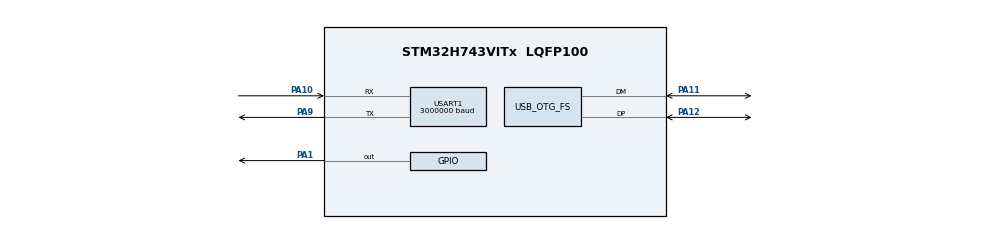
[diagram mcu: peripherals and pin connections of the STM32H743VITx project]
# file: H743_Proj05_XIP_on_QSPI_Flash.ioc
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Mcu.Family=STM32H7
Mcu.Name=STM32H743VITx
Mcu.Package=LQFP100
NVIC.OTG_FS_IRQn=true\:0\:0\:false\:false\:true\:false\:true
NVIC.PriorityGroup=NVIC_PRIORITYGROUP_4
NVIC.TIM8_UP_TIM13_IRQn=true\:0\:0\:false\:false\:true\:false\:true
NVIC.TimeBase=TIM8_UP_TIM13_IRQn
NVIC.TimeBaseIP=TIM13
PA1.GPIO_PuPd=GPIO_PULLUP
PA1.PinState=GPIO_PIN_SET
PA1.Signal=GPIO_Output
PA10.GPIO_Speed=GPIO_SPEED_FREQ_MEDIUM
PA10.Mode=Asynchronous
PA10.Signal=USART1_RX
PA11.GPIO_Speed=GPIO_SPEED_FREQ_MEDIUM
PA11.Mode=Device_Only
PA11.Signal=USB_OTG_FS_DM
PA12.GPIO_PuPd=GPIO_NOPULL
PA12.GPIO_Speed=GPIO_SPEED_FREQ_MEDIUM
PA12.Mode=Device_Only
PA12.Signal=USB_OTG_FS_DP
PA13\ (JTMS/SWDIO).Mode=Serial_Wire
PA13\ (JTMS/SWDIO).Signal=DEBUG_JTMS-SWDIO
PA14\ (JTCK/SWCLK).Mode=Serial_Wire
PA14\ (JTCK/SWCLK).Signal=DEBUG_JTCK-SWCLK
PA9.GPIO_Speed=GPIO_SPEED_FREQ_MEDIUM
PA9.Mode=Asynchronous
PA9.Signal=USART1_TX
PB6.GPIO_PuPd=GPIO_PULLUP
PB6.GPIO_Speed=GPIO_SPEED_FREQ_HIGH
PB6.Signal=QUADSPI_BK1_NCS
PC14-OSC32_IN\ (OSC32_IN).Mode=LSE-External-Oscillator
PC14-OSC32_IN\ (OSC32_IN).Signal=RCC_OSC32_IN
PC15-OSC32_OUT\ (OSC32_OUT).Mode=LSE-External-Oscillator
PC15-OSC32_OUT\ (OSC32_OUT).Signal=RCC_OSC32_OUT
PH0-OSC_IN\ (PH0).Mode=HSE-External-Oscillator
PH0-OSC_IN\ (PH0).Signal=RCC_OSC_IN
PH1-OSC_OUT\ (PH1).Mode=HSE-External-Oscillator
PH1-OSC_OUT\ (PH1).Signal=RCC_OSC_OUT
ProjectManager.HeapSize=0x200
ProjectManager.StackSize=0x400
ProjectManager.TargetToolchain=STM32CubeIDE
RCC.ADCFreq_Value=50390625
RCC.APB1Freq_Value=120000000
RCC.APB2Freq_Value=120000000
RCC.APB3Freq_Value=120000000
RCC.APB4Freq_Value=120000000
RCC.CortexFreq_Value=480000000
RCC.D1PPRE=RCC_APB3_DIV2
RCC.D2PPRE1=RCC_APB1_DIV2
RCC.D2PPRE2=RCC_APB2_DIV2
RCC.D3PPRE=RCC_APB4_DIV2
RCC.DIVM1=5
RCC.DIVM3=5
RCC.DIVN1=192
RCC.DIVN3=192
RCC.DIVQ3=20
RCC.HCLKFreq_Value=240000000
RCC.HPRE=RCC_HCLK_DIV2
RCC.RTCClockSelection=RCC_RTCCLKSOURCE_LSE
RCC.SYSCLKFreq_VALUE=480000000
RCC.SYSCLKSource=RCC_SYSCLKSOURCE_PLLCLK
RCC.USBCLockSelection=RCC_USBCLKSOURCE_PLL3
RCC.USBFreq_Value=48000000
USART1.BaudRate=3000000
USART1.VirtualMode-Asynchronous=VM_ASYNC
USB_DEVICE.CLASS_NAME_FS=CDC
USB_DEVICE.VirtualMode-CDC_FS=Cdc
USB_DEVICE.VirtualModeFS=Cdc_FS
USB_OTG_FS.VirtualMode=Device_Only
VP_RTC_VS_RTC_Activate.Mode=RTC_Enabled
VP_SYS_VS_tim13.Mode=TIM13
VP_USB_DEVICE_VS_USB_DEVICE_CDC_FS.Mode=CDC_FS
board=custom

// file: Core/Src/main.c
/* USER CODE BEGIN Header */
/**
  ******************************************************************************
  * @file           : main.c
  * @brief          : Main program body
  ******************************************************************************
  * @attention
  *
  * <h2><center>&copy; Copyright (c) 2020 STMicroelectronics.
  * All rights reserved.</center></h2>
  *
  * This software component is licensed by ST under BSD 3-Clause license,
  * the "License"; You may not use this file except in compliance with the
  * License. You may obtain a copy of the License at:
  *                        opensource.org/licenses/BSD-3-Clause
  *
  ******************************************************************************
  */
/* USER CODE END Header */

#include "main.h"
#include "usb_device.h"

/* USER CODE BEGIN Includes */
#include "usbd_cdc_if.h"
/* USER CODE END Includes */

RTC_HandleTypeDef hrtc;

UART_HandleTypeDef huart1;

/* USER CODE BEGIN PV */
char sOutput[160];
/* USER CODE END PV */

void SystemClock_Config(void);
static void MX_GPIO_Init(void);
static void MX_RTC_Init(void);
static void MX_USART1_UART_Init(void);

int main(void)
{
  /* USER CODE BEGIN 1 */

	/* Enable I-Cache */
	//SCB_EnableICache();

	/* Enable D-Cache */
	//SCB_EnableDCache();

  /* USER CODE END 1 */

  /* MCU Configuration--------------------------------------------------------*/

  /* Reset of all peripherals, Initializes the Flash interface and the Systick. */
  HAL_Init();

  /* Configure the system clock */
  SystemClock_Config();

  /* Initialize all configured peripherals */
  MX_GPIO_Init();
  MX_RTC_Init();
  MX_USART1_UART_Init();
  MX_USB_DEVICE_Init();

  /* Infinite loop */
  /* USER CODE BEGIN WHILE */
  uint16_t i=0;
  while (1)
  {
		snprintf(sOutput,159,"[H743_Proj05_XIP_on_QSPI_flash]: In while cycle %04X.\r\n",i++);
		HAL_UART_Transmit(&huart1, (uint8_t*)sOutput,strlen(sOutput), 0xFFFF);
		CDC_Transmit_FS((uint8_t*)sOutput,strlen(sOutput));
		HAL_GPIO_TogglePin(GPIOA, GPIO_PIN_1);
		HAL_Delay(2);
    /* USER CODE END WHILE */

  }
}

void SystemClock_Config(void)
{
  RCC_OscInitTypeDef RCC_OscInitStruct = {0};
  RCC_ClkInitTypeDef RCC_ClkInitStruct = {0};
  RCC_PeriphCLKInitTypeDef PeriphClkInitStruct = {0};

  /** Supply configuration update enable
  */
  HAL_PWREx_ConfigSupply(PWR_LDO_SUPPLY);
  /** Configure the main internal regulator output voltage
  */
  __HAL_PWR_VOLTAGESCALING_CONFIG(PWR_REGULATOR_VOLTAGE_SCALE0);

  while(!__HAL_PWR_GET_FLAG(PWR_FLAG_VOSRDY)) {}
  /** Configure LSE Drive Capability
  */
  HAL_PWR_EnableBkUpAccess();
  __HAL_RCC_LSEDRIVE_CONFIG(RCC_LSEDRIVE_LOW);
  /** Macro to configure the PLL clock source
  */
  __HAL_RCC_PLL_PLLSOURCE_CONFIG(RCC_PLLSOURCE_HSE);
  /** Initializes the CPU, AHB and APB busses clocks
  */
  RCC_OscInitStruct.OscillatorType = RCC_OSCILLATORTYPE_HSE|RCC_OSCILLATORTYPE_LSE;
  RCC_OscInitStruct.HSEState = RCC_HSE_ON;
  RCC_OscInitStruct.LSEState = RCC_LSE_ON;
  RCC_OscInitStruct.PLL.PLLState = RCC_PLL_ON;
  RCC_OscInitStruct.PLL.PLLSource = RCC_PLLSOURCE_HSE;
  RCC_OscInitStruct.PLL.PLLM = 5;
  RCC_OscInitStruct.PLL.PLLN = 192;
  RCC_OscInitStruct.PLL.PLLP = 2;
  RCC_OscInitStruct.PLL.PLLQ = 2;
  RCC_OscInitStruct.PLL.PLLR = 2;
  RCC_OscInitStruct.PLL.PLLRGE = RCC_PLL1VCIRANGE_2;
  RCC_OscInitStruct.PLL.PLLVCOSEL = RCC_PLL1VCOWIDE;
  RCC_OscInitStruct.PLL.PLLFRACN = 0;
  if (HAL_RCC_OscConfig(&RCC_OscInitStruct) != HAL_OK)
  {
    Error_Handler();
  }
  /** Initializes the CPU, AHB and APB busses clocks
  */
  RCC_ClkInitStruct.ClockType = RCC_CLOCKTYPE_HCLK|RCC_CLOCKTYPE_SYSCLK
                              |RCC_CLOCKTYPE_PCLK1|RCC_CLOCKTYPE_PCLK2
                              |RCC_CLOCKTYPE_D3PCLK1|RCC_CLOCKTYPE_D1PCLK1;
  RCC_ClkInitStruct.SYSCLKSource = RCC_SYSCLKSOURCE_PLLCLK;
  RCC_ClkInitStruct.SYSCLKDivider = RCC_SYSCLK_DIV1;
  RCC_ClkInitStruct.AHBCLKDivider = RCC_HCLK_DIV2;
  RCC_ClkInitStruct.APB3CLKDivider = RCC_APB3_DIV2;
  RCC_ClkInitStruct.APB1CLKDivider = RCC_APB1_DIV2;
  RCC_ClkInitStruct.APB2CLKDivider = RCC_APB2_DIV2;
  RCC_ClkInitStruct.APB4CLKDivider = RCC_APB4_DIV2;

  if (HAL_RCC_ClockConfig(&RCC_ClkInitStruct, FLASH_LATENCY_4) != HAL_OK)
  {
    Error_Handler();
  }
  PeriphClkInitStruct.PeriphClockSelection = RCC_PERIPHCLK_RTC|RCC_PERIPHCLK_USART1
                              |RCC_PERIPHCLK_USB;
  PeriphClkInitStruct.PLL3.PLL3M = 5;
  PeriphClkInitStruct.PLL3.PLL3N = 192;
  PeriphClkInitStruct.PLL3.PLL3P = 2;
  PeriphClkInitStruct.PLL3.PLL3Q = 20;
  PeriphClkInitStruct.PLL3.PLL3R = 2;
  PeriphClkInitStruct.PLL3.PLL3RGE = RCC_PLL3VCIRANGE_2;
  PeriphClkInitStruct.PLL3.PLL3VCOSEL = RCC_PLL3VCOWIDE;
  PeriphClkInitStruct.PLL3.PLL3FRACN = 0;
  PeriphClkInitStruct.Usart16ClockSelection = RCC_USART16CLKSOURCE_D2PCLK2;
  PeriphClkInitStruct.UsbClockSelection = RCC_USBCLKSOURCE_PLL3;
  PeriphClkInitStruct.RTCClockSelection = RCC_RTCCLKSOURCE_LSE;
  if (HAL_RCCEx_PeriphCLKConfig(&PeriphClkInitStruct) != HAL_OK)
  {
    Error_Handler();
  }
  /** Enable USB Voltage detector
  */
  HAL_PWREx_EnableUSBVoltageDetector();
}

static void MX_RTC_Init(void)
{

  /** Initialize RTC Only
  */
  hrtc.Instance = RTC;
  hrtc.Init.HourFormat = RTC_HOURFORMAT_24;
  hrtc.Init.AsynchPrediv = 127;
  hrtc.Init.SynchPrediv = 255;
  hrtc.Init.OutPut = RTC_OUTPUT_DISABLE;
  hrtc.Init.OutPutPolarity = RTC_OUTPUT_POLARITY_HIGH;
  hrtc.Init.OutPutType = RTC_OUTPUT_TYPE_OPENDRAIN;
  hrtc.Init.OutPutRemap = RTC_OUTPUT_REMAP_NONE;
  if (HAL_RTC_Init(&hrtc) != HAL_OK)
  {
    Error_Handler();
  }

}

static void MX_USART1_UART_Init(void)
{

  huart1.Instance = USART1;
  huart1.Init.BaudRate = 3000000;
  huart1.Init.WordLength = UART_WORDLENGTH_8B;
  huart1.Init.StopBits = UART_STOPBITS_1;
  huart1.Init.Parity = UART_PARITY_NONE;
  huart1.Init.Mode = UART_MODE_TX_RX;
  huart1.Init.HwFlowCtl = UART_HWCONTROL_NONE;
  huart1.Init.OverSampling = UART_OVERSAMPLING_16;
  huart1.Init.OneBitSampling = UART_ONE_BIT_SAMPLE_DISABLE;
  huart1.Init.ClockPrescaler = UART_PRESCALER_DIV1;
  huart1.AdvancedInit.AdvFeatureInit = UART_ADVFEATURE_NO_INIT;
  if (HAL_UART_Init(&huart1) != HAL_OK)
  {
    Error_Handler();
  }
  if (HAL_UARTEx_SetTxFifoThreshold(&huart1, UART_TXFIFO_THRESHOLD_1_8) != HAL_OK)
  {
    Error_Handler();
  }
  if (HAL_UARTEx_SetRxFifoThreshold(&huart1, UART_RXFIFO_THRESHOLD_1_8) != HAL_OK)
  {
    Error_Handler();
  }
  if (HAL_UARTEx_DisableFifoMode(&huart1) != HAL_OK)
  {
    Error_Handler();
  }

}

static void MX_GPIO_Init(void)
{
  GPIO_InitTypeDef GPIO_InitStruct = {0};

  /* GPIO Ports Clock Enable */
  __HAL_RCC_GPIOC_CLK_ENABLE();
  __HAL_RCC_GPIOH_CLK_ENABLE();
  __HAL_RCC_GPIOA_CLK_ENABLE();
  __HAL_RCC_GPIOB_CLK_ENABLE();

  /*Configure GPIO pin Output Level */
  HAL_GPIO_WritePin(GPIOA, GPIO_PIN_1, GPIO_PIN_SET);

  /*Configure GPIO pin : PA1 */
  GPIO_InitStruct.Pin = GPIO_PIN_1;
  GPIO_InitStruct.Mode = GPIO_MODE_OUTPUT_PP;
  GPIO_InitStruct.Pull = GPIO_PULLUP;
  GPIO_InitStruct.Speed = GPIO_SPEED_FREQ_LOW;
  HAL_GPIO_Init(GPIOA, &GPIO_InitStruct);

  /*Configure GPIO pin : PB6 */
  GPIO_InitStruct.Pin = GPIO_PIN_6;
  GPIO_InitStruct.Mode = GPIO_MODE_AF_PP;
  GPIO_InitStruct.Pull = GPIO_PULLUP;
  GPIO_InitStruct.Speed = GPIO_SPEED_FREQ_HIGH;
  GPIO_InitStruct.Alternate = GPIO_AF10_QUADSPI;
  HAL_GPIO_Init(GPIOB, &GPIO_InitStruct);

}

void HAL_TIM_PeriodElapsedCallback(TIM_HandleTypeDef *htim)
{
  if (htim->Instance == TIM13) {
    HAL_IncTick();
  }
}

void Error_Handler(void)
{
}

/************************ (C) COPYRIGHT STMicroelectronics *****END OF FILE****/
